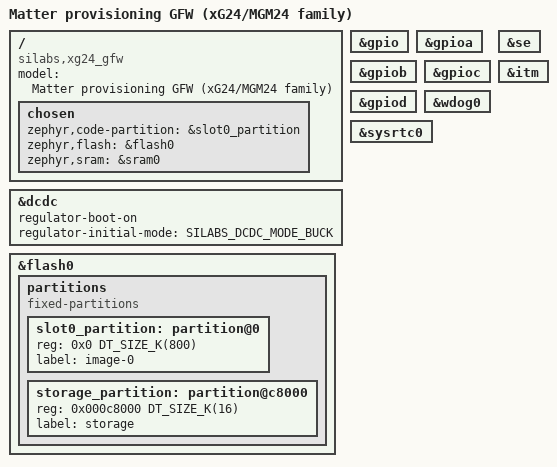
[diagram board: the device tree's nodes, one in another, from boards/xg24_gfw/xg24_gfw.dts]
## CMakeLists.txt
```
# *******************************************************************************
# License
# <b>Copyright 2026 Silicon Laboratories Inc. www.silabs.com</b>
# *******************************************************************************
# The licensor of this software is Silicon Laboratories Inc.  Your use of this
# software is governed by the terms of Silicon Labs Master Software License
# agreement (MSLA) available at
# www.silabs.com/about-us/legal/master-software-license-agreement.  This
# software is distributed to you in Source Code format and is governed by the
# sections of the MSLA applicable to Source Code.
# *******************************************************************************

cmake_minimum_required(VERSION 3.20)

if(DEFINED CHIP_ROOT)
  get_filename_component(CHIP_ROOT ${CHIP_ROOT} REALPATH)
else()
  get_filename_component(CHIP_ROOT ${CMAKE_CURRENT_SOURCE_DIR}/../../../.. REALPATH)
endif()

set(PROVISION_SUPPORT_DIR ${CHIP_ROOT}/third_party/silabs/matter_support/provision)

list(APPEND ZEPHYR_EXTRA_MODULES ${CHIP_ROOT}/config/silabs)
list(APPEND BOARD_ROOT ${CMAKE_CURRENT_SOURCE_DIR})
find_package(Zephyr HINTS $ENV{ZEPHYR_BASE})

project(matter-provision-gfw)

include(${CHIP_ROOT}/config/silabs/app/enable-gnu-std.cmake)

target_compile_options(app PRIVATE -Werror -Wno-error=maybe-uninitialized)

set(PROV_SDK ${CHIP_ROOT}/examples/platform/silabs/provision)

if(NOT DEFINED PROVISION_LIBS_DIR)
  set(PROVISION_LIBS_DIR ${PROVISION_SUPPORT_DIR}/libs)
endif()

# Match SLC GFW / matter_sdk ABI selection: SiWx917 -> m4-softfp, EFR Series 2 -> m33-hard.
if(CONFIG_SOC_FAMILY_SILABS_SIWX91X)
  set(PROVISION_CORE_LIB ${PROVISION_LIBS_DIR}/libProvision-m4-softfp.a)
else()
  set(PROVISION_CORE_LIB ${PROVISION_LIBS_DIR}/libProvision-m33-hard.a)
endif()

if(NOT EXISTS ${PROVISION_CORE_LIB})
  message(FATAL_ERROR
    "Missing Provision Core archive: ${PROVISION_CORE_LIB}\n"
    "Check out the third_party/silabs/matter_support submodule "
    "(or pass -DPROVISION_LIBS_DIR=...).")
endif()

target_include_directories(app PRIVATE
    include
    ${PROVISION_SUPPORT_DIR}
    ${CHIP_ROOT}/examples
    ${CHIP_ROOT}/examples/platform/silabs
    ${CHIP_ROOT}/src/include
    ${CHIP_ROOT}/src
    ${CHIP_ROOT}/third_party/nlio/include
    ${CHIP_ROOT}/third_party/nlassert/include
    # EFR boards get these via the Silabs PSA driver module; SiWx917 GFW does not.
    ${ZEPHYR_HAL_SILABS_MODULE_DIR}/simplicity_sdk/platform/security/sl_component/sl_mbedtls_support/inc
    ${ZEPHYR_HAL_SILABS_MODULE_DIR}/simplicity_sdk/platform/security/sl_component/sl_psa_driver/inc
)

target_sources(app PRIVATE
    src/main.cpp
    ${PROV_SDK}/ProvisionCryptoPSA.cpp
    ${PROV_SDK}/ProvisionStorageReaderCommon.cpp
    ${PROV_SDK}/ProvisionStorageCustom.cpp
    ${PROV_SDK}/ProvisionChannelRTT.cpp
    ${PROV_SDK}/zephyr/ProvisionStorageReader.cpp
    ${PROV_SDK}/zephyr/ProvisionStorageWriter.cpp

    # Contains implementation of sl_psa_get_most_secure_key_location()
    # Silicon Labs Zephyr links the header file, but not the implementation as of 2026-08-14.
    #
    # Message from the Zephyr team:
    # "Since SiSDK for Zephyr is currently using Zephyr's fork of PSA Crypto, rather than the SiSDK
    # fork of PSA Crypto, we intentionally didn't include some of these SL extensions to PSA Crypto, 
    # since some of them rely on patches in PSA Crypto that the Zephyr fork doesn't have. That specific 
    # function seems safe to use, though, so we should probably include that file."
    # 
    # Adding it here until the Zephyr team includes the implementation in the Zephyr module.
    ${ZEPHYR_HAL_SILABS_MODULE_DIR}/simplicity_sdk/platform/security/sl_component/sl_mbedtls_support/src/sl_psa_crypto.c
)

target_link_libraries(app PRIVATE ${PROVISION_CORE_LIB})

target_compile_definitions(app PRIVATE
    SL_MATTER_PROVISION_CHANNEL_ENABLED=1
    SILABS_PROVISION_PROTOCOL_V1=0
    SL_PROVISION_GENERATOR=1
    CHIP_CONFIG_MEMORY_MGMT_MALLOC=1
    CHIP_DEVICE_LAYER_TARGET_ZEPHYR=1
)

# SiWx917 device headers do not define FLASH_PAGE_SIZE (EFR does). Match FreeRTOS
# SiWx917 SDK / DT erase-block-size (4096).
if(CONFIG_SOC_FAMILY_SILABS_SIWX91X)
    target_compile_definitions(app PRIVATE FLASH_PAGE_SIZE=4096)
endif()
```

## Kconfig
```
config MATTER_PROVISIONING_DEFER_SETTINGS_INIT
	bool "Defer secure-storage Settings initialization"
	default y
	help
	  Defer the secure-storage Settings mount. Used for the provisioning
	  protocol to supply the NVS geometry at runtime.

source "Kconfig.zephyr"
```

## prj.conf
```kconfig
CONFIG_CHIP=y
CONFIG_STD_CPP17=y
CONFIG_REBOOT=y

CONFIG_SETTINGS=y
CONFIG_MATTER_PROVISIONING_DEFER_SETTINGS_INIT=y
CONFIG_NVS=y
CONFIG_FLASH=y
CONFIG_FLASH_MAP=y
CONFIG_STREAM_FLASH=y

CONFIG_USE_SEGGER_RTT=y
CONFIG_SEGGER_RTT_BUFFER_SIZE_UP=1024
CONFIG_SEGGER_RTT_BUFFER_SIZE_DOWN=1024

CONFIG_MAIN_STACK_SIZE=8192
CONFIG_SYSTEM_WORKQUEUE_STACK_SIZE=2048
CONFIG_HEAP_MEM_POOL_SIZE=24576

CONFIG_MBEDTLS=y
CONFIG_PSA_CRYPTO=y
CONFIG_CHIP_CRYPTO_PSA=y
CONFIG_SECURE_STORAGE_ITS_MAX_DATA_SIZE=256
CONFIG_MBEDTLS_HEAP_SIZE=16384
CONFIG_MBEDTLS_PK_WRITE_C=y
CONFIG_MBEDTLS_X509_CSR_WRITE_C=y
CONFIG_MBEDTLS_X509_CSR_PARSE_C=y
CONFIG_MBEDTLS_PEM_WRITE_C=y

CONFIG_LOG=y
CONFIG_LOG_MODE_MINIMAL=y
CONFIG_PRINTK=y

CONFIG_SHELL=n
CONFIG_BT=n
CONFIG_NET_L2_OPENTHREAD=n
CONFIG_OPENTHREAD=n
CONFIG_DNS_SD=n
CONFIG_CHIP_LIB_SHELL=n
CONFIG_CHIP_ENABLE_PAIRING_AUTOSTART=n
CONFIG_CHIP_OTA_REQUESTOR=n

CONFIG_POSIX_AEP_CHOICE_NONE=y
CONFIG_THREAD_LOCAL_STORAGE=y
```

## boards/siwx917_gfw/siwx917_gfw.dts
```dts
/*******************************************************************************
 * # License
 * <b>Copyright 2026 Silicon Laboratories Inc. www.silabs.com</b>
 *******************************************************************************
 *
 * The licensor of this software is Silicon Laboratories Inc.  Your use of this
 * software is governed by the terms of Silicon Labs Master Software License
 * Agreement (MSLA) available at
 * www.silabs.com/about-us/legal/master-software-license-agreement.  This
 * software is distributed to you in Source Code format and is governed by the
 * sections of the MSLA applicable to Source Code.
 *
 ******************************************************************************/

/dts-v1/;
#include <zephyr/dt-bindings/pinctrl/silabs/siwx91x-pinctrl.h>
#include <silabs/siwg917m111mgtba.dtsi>

/ {
	model = "Matter provisioning GFW (SiWx917)";
	compatible = "silabs,siwx917_gfw", "silabs,siwg917";

	chosen {
		zephyr,code-partition = &code_partition;
		zephyr,settings-partition = &settings_partition;
		zephyr,flash = &flash0;
		zephyr,sram = &sram0;
	};
};

&cpu0 {
	clock-frequency = <180000000>;
};

/* NWP init requires pinctrl even when WiFi is off
 * (flash driver selects SILABS_SIWX91X_NWP → sl_wifi_init).
 */
&pinctrl0 {
	nwp_default: nwp_default {
		group {
			pinmux = <WIFI_ANT0_ULP0>, <WIFI_ANT1_ULP4>, <WIFI_ANT2_ULP5>;
		};
	};
};

&nwp {
	pinctrl-0 = <&nwp_default>;
	pinctrl-names = "default";
	antenna-selection = "ext-gpios";
};

&flash0 {
	partitions {
		compatible = "fixed-partitions";
		#address-cells = <1>;
		#size-cells = <1>;

		code_partition: partition@202000 {
			compatible = "zephyr,mapped-partition";
			reg = <0x00202000 DT_SIZE_K(1912)>;
			label = "code_partition";
		};

		settings_partition: partition@3e1000 {
			reg = <0x003e1000 DT_SIZE_K(32)>;
			label = "settings";
		};
	};
};

&bt_hci0 {
	status = "okay";
};

&wifi0 {
	status = "okay";
};
```

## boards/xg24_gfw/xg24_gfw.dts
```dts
/*******************************************************************************
 * # License
 * <b>Copyright 2026 Silicon Laboratories Inc. www.silabs.com</b>
 *******************************************************************************
 *
 * The licensor of this software is Silicon Laboratories Inc.  Your use of this
 * software is governed by the terms of Silicon Labs Master Software License
 * Agreement (MSLA) available at
 * www.silabs.com/about-us/legal/master-software-license-agreement.  This
 * software is distributed to you in Source Code format and is governed by the
 * sections of the MSLA applicable to Source Code.
 *
 ******************************************************************************/

/dts-v1/;
#include <silabs/xg24/efr32mg24b220f1536im48.dtsi>
#include <silabs/xg24/clock-hfrcodpll.dtsi>
#include <silabs/xg24/clock-lfxo.dtsi>
#include <zephyr/dt-bindings/regulator/silabs_dcdc.h>

/ {
	model = "Matter provisioning GFW (xG24/MGM24 family)";
	compatible = "silabs,xg24_gfw", "silabs,efr32mg24";

	chosen {
		zephyr,code-partition = &slot0_partition;
		zephyr,flash = &flash0;
		zephyr,sram = &sram0;
	};
};

&gpio {
	status = "okay";
};

&gpioa {
	status = "okay";
};

&gpiob {
	status = "okay";
};

&gpioc {
	status = "okay";
};

&gpiod {
	status = "okay";
};

&se {
	status = "okay";
};

&dcdc {
	regulator-boot-on;
	regulator-initial-mode = <SILABS_DCDC_MODE_BUCK>;
	status = "okay";
};

&wdog0 {
	status = "okay";
};

&sysrtc0 {
	status = "okay";
};

&itm {
	status = "okay";
};

&flash0 {
	partitions {
		compatible = "fixed-partitions";
		#address-cells = <1>;
		#size-cells = <1>;

		/*
		 * Internal flash layout (1024 KB total):
		 *   0x000000 - 0x0C7FFF  slot0   (800 KB, code)
		 *   0x0C8000 - 0x0CBFFF  storage (16 KB, 2 x 8 KB erase blocks)
		 */
		slot0_partition: partition@0 {
			reg = <0x0 DT_SIZE_K(800)>;
			label = "image-0";
		};

		storage_partition: partition@c8000 {
			reg = <0x000c8000 DT_SIZE_K(16)>;
			label = "storage";
		};
	};
};
```

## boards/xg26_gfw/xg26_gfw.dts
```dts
/*******************************************************************************
 * # License
 * <b>Copyright 2026 Silicon Laboratories Inc. www.silabs.com</b>
 *******************************************************************************
 *
 * The licensor of this software is Silicon Laboratories Inc.  Your use of this
 * software is governed by the terms of Silicon Labs Master Software License
 * Agreement (MSLA) available at
 * www.silabs.com/about-us/legal/master-software-license-agreement.  This
 * software is distributed to you in Source Code format and is governed by the
 * sections of the MSLA applicable to Source Code.
 *
 ******************************************************************************/

/dts-v1/;
#include <silabs/xg26/efr32mg26b510f3200il136.dtsi>
#include <silabs/xg26/clock-hfrcodpll.dtsi>
#include <silabs/xg26/clock-lfxo.dtsi>
#include <zephyr/dt-bindings/regulator/silabs_dcdc.h>

/ {
	model = "Matter provisioning GFW (xG26/MGM26 family)";
	compatible = "silabs,xg26_gfw", "silabs,efr32mg26";

	chosen {
		zephyr,code-partition = &slot0_partition;
		zephyr,flash = &flash0;
		zephyr,sram = &sram0;
	};
};

&gpio {
	status = "okay";
};

&gpioa {
	status = "okay";
};

&gpiob {
	status = "okay";
};

&gpioc {
	status = "okay";
};

&gpiod {
	status = "okay";
};

&se {
	status = "okay";
};

&dcdc {
	regulator-boot-on;
	regulator-initial-mode = <SILABS_DCDC_MODE_BUCK>;
	status = "okay";
};

&wdog0 {
	status = "okay";
};

&sysrtc0 {
	status = "okay";
};

&itm {
	status = "okay";
};

&flash0 {
	partitions {
		compatible = "fixed-partitions";
		#address-cells = <1>;
		#size-cells = <1>;

		/*
		 * Internal flash layout (2048 KB total):
		 *   0x000000 - 0x0C7FFF  slot0   (800 KB, code)
		 *   0x0C8000 - 0x0CBFFF  storage (16 KB, 2 x 8 KB erase blocks)
		 */
		slot0_partition: partition@0 {
			reg = <0x0 DT_SIZE_K(800)>;
			label = "image-0";
		};

		storage_partition: partition@c8000 {
			reg = <0x000c8000 DT_SIZE_K(16)>;
			label = "storage";
		};

	};
};
```

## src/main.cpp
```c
/*****************************************************************************
 * @file main.cpp
 * @brief main() function.
 *******************************************************************************
 * # License
 * <b>Copyright 2026 Silicon Laboratories Inc. www.silabs.com</b>
 *******************************************************************************
 *
 * The licensor of this software is Silicon Laboratories Inc.  Your use of this
 * software is governed by the terms of Silicon Labs Master Software License
 * Agreement (MSLA) available at
 * www.silabs.com/about-us/legal/master-software-license-agreement.  This
 * software is distributed to you in Source Code format and is governed by the
 * sections of the MSLA applicable to Source Code.
 *
 ******************************************************************************/

#include <headers/ProvisionManager.h>
#include <lib/support/CHIPMem.h>
#include <provision/ProvisionChannel.h>
#include <provision/ProvisionCrypto.h>
#include <provision/ProvisionStorageReader.h>
#include <provision/ProvisionStorageWriter.h>

#include <zephyr/kernel.h>
#include <zephyr/sys/reboot.h>

using namespace chip::DeviceLayer::Silabs::Provision;

void resetDevice()
{
    sys_reboot(SYS_REBOOT_COLD);
}

int main()
{
    chip::Platform::MemoryInit();
    ChipLogError(DeviceLayer, "Starting Matter Provisioning");

    Manager & manager = Manager::GetInstance();

    // NVS geometry comes from the first host packet (Protocol V2 calls
    // ProvisionStorageWriter::Initialize). Do not initialize storage here.
    manager.SetStorageBackend(ProvisionStorageReader::GetInstance(), &ProvisionStorageWriter::GetInstance());
    manager.SetCryptoProvider(ProvisionCrypto::GetInstance());
    manager.SetChannel(ProvisionChannel::GetInstance());
    manager.SetResetHandler(resetDevice);
    if (manager.Init(true) != CHIP_NO_ERROR)
    {
        ChipLogError(DeviceLayer, "Failed to initialize provisioning manager");
        return -1;
    }

    while (manager.Step())
    {
        k_yield();
    }

    return 0;
}
```
